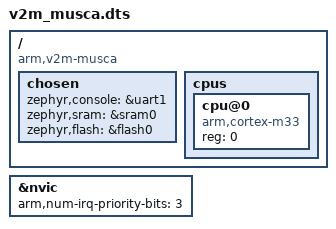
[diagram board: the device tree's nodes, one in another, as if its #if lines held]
/*
 * Copyright (c) 2018 Linaro Limited
 *
 * SPDX-License-Identifier: Apache-2.0
 */

/dts-v1/;

#include <arm/armv8-m.dtsi>

#if defined (CONFIG_ARM_NONSECURE_FIRMWARE)
#include "v2m_musca-nonsecure.dtsi"
#else
#include "v2m_musca-secure.dtsi"
#endif

/ {
	compatible = "arm,v2m-musca";
	#address-cells = <1>;
	#size-cells = <1>;

	chosen {
		zephyr,console = &uart1;
		zephyr,sram = &sram0;
		zephyr,flash = &flash0;
	};

	cpus {
		#address-cells = <1>;
		#size-cells = <0>;

		cpu@0 {
			device_type = "cpu";
			compatible = "arm,cortex-m33";
			reg = <0>;
		};
	};
};

&nvic {
	arm,num-irq-priority-bits = <3>;
};
